VERSION ""

NS_ :

BS_:

BU_:

BO_ 3221225472 VECTOR__INDEPENDENT_SIG_MSG: 0 Vector__XXX
 SG_ reserved : 9|7@1+ (1,0) [0|0] "" Vector__XXX
 SG_ velocity_valid : 97|1@1+ (1,0) [0|0] "" Vector__XXX
 SG_ position_valid : 96|1@1+ (1,0) [0|0] "" Vector__XXX
 SG_ throttle : 64|32@1- (1,0) [0|0] "Percent" Vector__XXX
 SG_ velocity : 32|32@1- (1,0) [0|0] "Rotations per Second" Vector__XXX
 SG_ data1 : 0|64@1+ (1,0) [0|0] "" Vector__XXX
 SG_ data2 : 64|64@1+ (1,0) [0|0] "" Vector__XXX
 SG_ data3 : 128|64@1+ (1,0) [0|0] "" Vector__XXX
 SG_ NewSignal_0004 : 192|8@1+ (1,0) [0|0] "" Vector__XXX
 SG_ timestamp : 80|16@1+ (1,0) [0|0] "" Vector__XXX
 SG_ NewSignal_0017 : 40|8@1+ (1,0) [0|0] "" Vector__XXX
 SG_ NewSignal_0018 : 48|8@1+ (1,0) [0|0] "" Vector__XXX
 SG_ address : 0|8@1+ (1,0) [0|0] "" Vector__XXX
 SG_ value : 8|32@1+ (1,0) [0|0] "" Vector__XXX
 SG_ apply : 40|1@1+ (1,0) [0|0] "" Vector__XXX

BO_ 2148532224 BMCModeCmd: 2 Vector__XXX
 SG_ mode : 0|8@1+ (1,0) [0|0] "" Vector__XXX
 SG_ enable : 8|1@1+ (1,0) [0|0] "" Vector__XXX

BO_ 2148597760 BMCTargetCmd: 5 Vector__XXX
 SG_ target : 0|32@1- (1,0) [0|0] "" Vector__XXX
 SG_ target_valid : 32|1@1+ (1,0) [0|0] "" Vector__XXX

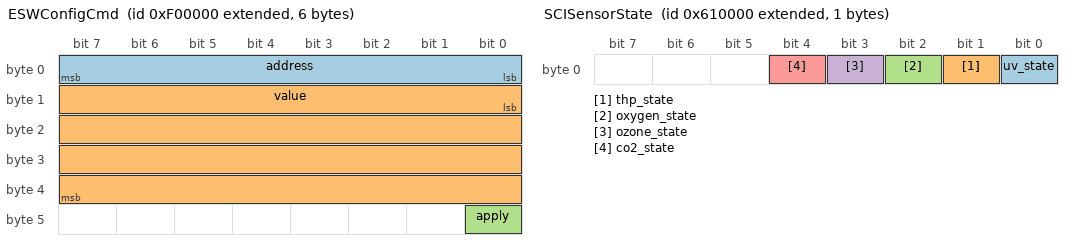
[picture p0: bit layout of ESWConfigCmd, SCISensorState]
BO_ 2163212288 ESWConfigCmd: 6 Vector__XXX
 SG_ address : 0|8@1+ (1,0) [0|0] "Memory Address" Vector__XXX
 SG_ value : 8|32@1+ (1,0) [0|0] "" Vector__XXX
 SG_ apply : 40|1@1+ (1,0) [0|0] "" Vector__XXX

BO_ 2148663296 BMCResetCmd: 1 Vector__XXX
 SG_ reset : 0|1@1+ (1,0) [0|0] "" Vector__XXX
 SG_ clear_faults : 1|1@1+ (1,0) [0|0] "" Vector__XXX

BO_ 2148728832 BMCMotorState: 16 Vector__XXX
 SG_ mode : 0|8@1+ (1,0) [0|0] "" Vector__XXX
 SG_ fault_code : 8|8@1+ (1,0) [0|0] "" Vector__XXX
 SG_ position : 16|32@1- (1,0) [0|0] "Radians" Vector__XXX
 SG_ velocity : 48|32@1- (1,0) [0|0] "Radians per Second" Vector__XXX
 SG_ limit_a : 112|1@1+ (1,0) [0|0] "" Vector__XXX
 SG_ limit_b : 113|1@1+ (1,0) [0|0] "" Vector__XXX
 SG_ is_stalled : 114|1@1+ (1,0) [0|0] "" Vector__XXX
 SG_ current : 80|32@1- (1,0) [0|0] "" Vector__XXX
 SG_ num_rx_dropped : 120|8@1+ (1,0) [0|255] "" Vector__XXX

BO_ 2163277824 ESWProbe: 4 Vector__XXX
 SG_ data : 0|32@1+ (1,0) [0|0] "" Vector__XXX

BO_ 2163343360 ESWAck: 4 Vector__XXX
 SG_ data : 0|32@1+ (1,0) [0|0] "" Vector__XXX

BO_ 2153775104 SCISensorData: 32 Vector__XXX
 SG_ uv_index : 0|32@1- (1,0) [0|0] "" Vector__XXX
 SG_ temperature : 32|32@1- (1,0) [0|0] "" Vector__XXX
 SG_ humidity : 64|32@1- (1,0) [0|0] "" Vector__XXX
 SG_ pressure : 96|32@1- (1,0) [0|0] "" Vector__XXX
 SG_ oxygen : 128|32@1- (1,0) [0|0] "" Vector__XXX
 SG_ ozone : 160|32@1- (1,0) [0|0] "" Vector__XXX
 SG_ co2 : 192|32@1- (1,0) [0|0] "" Vector__XXX

BO_ 2153840640 SCISensorState: 1 Vector__XXX
 SG_ uv_state : 0|1@1+ (1,0) [0|0] "" Vector__XXX
 SG_ thp_state : 1|1@1+ (1,0) [0|0] "" Vector__XXX
 SG_ oxygen_state : 2|1@1+ (1,0) [0|0] "" Vector__XXX
 SG_ ozone_state : 3|1@1+ (1,0) [0|0] "" Vector__XXX
 SG_ co2_state : 4|1@1+ (1,0) [0|0] "" Vector__XXX

BO_ 2152792064 SCIResetCommand: 1 Vector__XXX
 SG_ reset : 0|1@1+ (1,0) [0|0] "" Vector__XXX
 SG_ clear_faults : 1|1@1+ (1,0) [0|0] "" Vector__XXX

BO_ 2149580800 ABSEncoderState: 8 Vector__XXX
 SG_ position : 0|32@1- (1,0) [0|0] "" Vector__XXX
 SG_ velocity : 32|32@1- (1,0) [0|0] "" Vector__XXX

BO_ 2149646336 ABSResetCmd: 1 Vector__XXX
 SG_ reset : 0|1@1+ (1,0) [0|0] "" Vector__XXX
 SG_ clear_faults : 1|1@1+ (1,0) [0|0] "" Vector__XXX

BO_ 2149711872 ABSZeroCmd: 4 Vector__XXX
 SG_ offset : 0|32@1- (1,0) [0|0] "" Vector__XXX

BO_ 2154889216 PDLBResetCommand: 1 Vector__XXX
 SG_ reset : 0|1@1+ (1,0) [0|0] "" Vector__XXX
 SG_ clear_faults : 1|1@1+ (1,0) [0|0] "" Vector__XXX

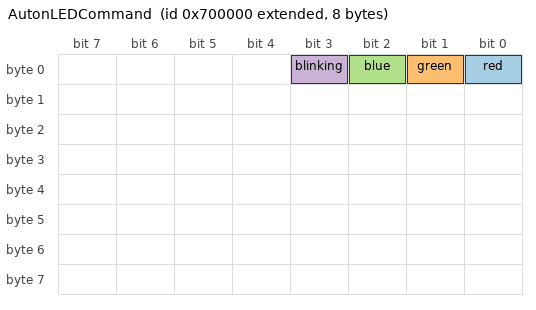
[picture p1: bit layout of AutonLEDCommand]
BO_ 2154823680 AutonLEDCommand: 8 Vector__XXX
 SG_ red : 0|1@1+ (1,0) [0|0] "" Vector__XXX
 SG_ green : 1|1@1+ (1,0) [0|0] "" Vector__XXX
 SG_ blue : 2|1@1+ (1,0) [0|0] "" Vector__XXX
 SG_ blinking : 3|1@1+ (1,0) [0|0] "" Vector__XXX

BO_ 2150629376 LIMState: 1 Vector__XXX
 SG_ lim_a : 0|1@1+ (1,0) [0|0] "" Vector__XXX
 SG_ lim_b : 1|1@1+ (1,0) [0|0] "" Vector__XXX

BO_ 2150694912 LIMResetCmd: 1 Vector__XXX
 SG_ reset : 0|1@1+ (1,0) [0|0] "" Vector__XXX
 SG_ clear_faults : 1|1@1+ (1,0) [0|0] "" Vector__XXX

BA_DEF_ BO_  "CANFD_BRS" ENUM  "0","1";
BA_DEF_  "BusType" STRING ;
BA_DEF_ BO_  "VFrameFormat" ENUM  "StandardCAN","ExtendedCAN","reserved","reserved","reserved","reserved","reserved","reserved","reserved","reserved","reserved","reserved","reserved","reserved","StandardCAN_FD","ExtendedCAN_FD";
BA_DEF_DEF_  "CANFD_BRS" "1";
BA_DEF_DEF_  "BusType" "";
BA_DEF_DEF_  "VFrameFormat" "StandardCAN";
BA_ "BusType" "CAN FD";
BA_ "VFrameFormat" BO_ 2148532224 15;
BA_ "VFrameFormat" BO_ 2148597760 15;
BA_ "VFrameFormat" BO_ 2163212288 15;
BA_ "VFrameFormat" BO_ 2148663296 15;
BA_ "VFrameFormat" BO_ 2148728832 15;
BA_ "VFrameFormat" BO_ 2163277824 15;
BA_ "VFrameFormat" BO_ 2163343360 15;
BA_ "VFrameFormat" BO_ 2153775104 15;
BA_ "VFrameFormat" BO_ 2153840640 15;
BA_ "VFrameFormat" BO_ 2152792064 15;
BA_ "VFrameFormat" BO_ 2149580800 15;
BA_ "VFrameFormat" BO_ 2149646336 15;
BA_ "VFrameFormat" BO_ 2149711872 15;
BA_ "VFrameFormat" BO_ 2154889216 15;
BA_ "VFrameFormat" BO_ 2154823680 15;
BA_ "VFrameFormat" BO_ 2150629376 15;
BA_ "VFrameFormat" BO_ 2150694912 15;
VAL_ 2148532224 mode 0 "Stopped" 1 "Fault" 5 "Throttle" 6 "Position" 7 "Velocity" ;
VAL_ 2148532224 enable 1 "Enabled" 0 "Disabled" ;
VAL_ 2148597760 target_valid 1 "Valid" 0 "Invalid" ;
VAL_ 2148663296 reset 1 "Enable" 0 "Disable" ;
VAL_ 2148663296 clear_faults 1 "Enable" 0 "Disable" ;
VAL_ 2148728832 mode 0 "Stopped" 1 "Fault" 5 "Throttle" 6 "Position" 7 "Velocity" ;
SIG_VALTYPE_ 2148597760 target : 1;
SIG_VALTYPE_ 2148728832 position : 1;
SIG_VALTYPE_ 2148728832 velocity : 1;
SIG_VALTYPE_ 2148728832 current : 1;
SIG_VALTYPE_ 2153775104 uv_index : 1;
SIG_VALTYPE_ 2153775104 temperature : 1;
SIG_VALTYPE_ 2153775104 humidity : 1;
SIG_VALTYPE_ 2153775104 pressure : 1;
SIG_VALTYPE_ 2153775104 oxygen : 1;
SIG_VALTYPE_ 2153775104 ozone : 1;
SIG_VALTYPE_ 2153775104 co2 : 1;
SIG_VALTYPE_ 2149580800 position : 1;
SIG_VALTYPE_ 2149580800 velocity : 1;
SIG_VALTYPE_ 2149711872 offset : 1;
